# PIC32CM5112SG00100 device description
Architecture: CORTEX-M23; Family: PIC32CM; Series: PIC32CMSG00
Registers are 32-bit, read-write, reset 0x0 unless marked. A register's access mark holds for its fields unless they carry their own. Offsets are from the block's base; [hi:lo] are bit positions; lines under a group give offsets from that group; {n}, {i} and the like mark numbered series; 'fields as' and 'values as' point back to an identical list; <NAME> marks a mode.

## ICB — Implementation Control Block
Instances: ICB 0xE000E000, ICB_NS 0xE002E000
0x04 ICTR ro reset not defined — Interrupt Controller Type Register
  [3:0] INTLINESNUM — Interrupt line set number
0x08 ACTLR reset not defined — Auxiliary Control Register

## IDAU — Implementation Defined Attribution Unit
Instances: IDAU 0x44012000
0x00 CTRL wo — Control
  [31:16] CMD — Command Register
    0xA501=ENABLE (Module Enable); 0xA502=DISABLE (Module Disable); 0xA503=WLCK (Write Lock)
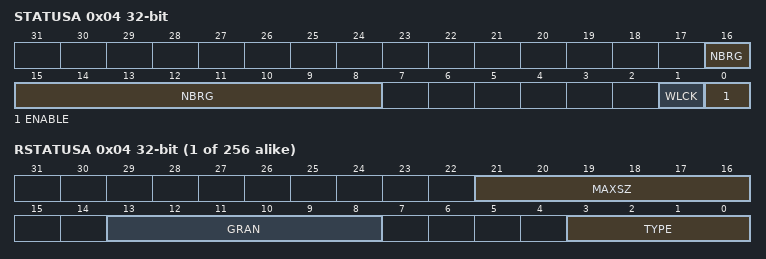
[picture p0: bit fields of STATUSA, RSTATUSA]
0x04 STATUSA ro reset not defined
  [16:8] NBRG — Number Of IDAU Regions
  [1] WLCK — Write Lock
  [0] ENABLE
0x08 STATUSB (atomic clear)
  [0] CFGERR — Configuration Error
{0x1000+0x10*i} REGIONS[{i}] (i=0..255) group
  0x00 RCTRL wo — Region Control
    [31:24] CMD <BLOCK> — Command
      90=CLRNONSEC (Clear IDAU region x Non-Secure State of block ARG (RSTATUSB[x].NONSEC[ARG]=0)); 91=SETNONSEC (Set IDAU region x Non-Secure State of block ARG (RSTATUSB[x].NONSEC[ARG]=1))
    [4:0] ARG <BLOCK> — Command Argument (Block ID)
    [31:24] CMD <WATERMARK> — Command
      92=WRSZ (Write IDAU region x Size (RSTATUSB[x].SIZE=ARG))
    [23:0] ARG <WATERMARK> — Command Argument (Watermark)
  0x04 RSTATUSA ro — Region Status A
    [21:16] MAXSZ — Command Argument Maximum Size
    [13:8] GRAN — Region Granularity
      0=GRAN_NA (Not Applicable); 5=GRAN_32B; 6=GRAN_64B; 7=GRAN_128B; 8=GRAN_256B; 9=GRAN_512B; 10=GRAN_1KB; 11=GRAN_2KB; 12=GRAN_4KB; 13=GRAN_8KB; 14=GRAN_16KB; 15=GRAN_32KB; 16=GRAN_64KB; 17=GRAN_128KB; 18=GRAN_256KB; 19=GRAN_512KB; 20=GRAN_1MB; 21=GRAN_2MB; 22=GRAN_4MB; 23=GRAN_8MB; 24=GRAN_16MB; 25=GRAN_32MB; 26=GRAN_64MB; 27=GRAN_128MB; 28=GRAN_256MB; 29=GRAN_512MB; 30=GRAN_1GB; 31=GRAN_2GB; 32=GRAN_4GB
    [3:0] TYPE — IDAU Region Type
      0=INVALID (Region is invalid); 1=SEC (Region is secure); 2=NONSEC (Region is non secure); 3=NONSEC_W (Region is non secure, the associated register group implements a watermark configuration); 4=SECnNONSEC_B (Region is either secure or non-secure, the associated register group implements a block configuration); 5=SECnNONSEC_L (Region is either secure or non-secure, configuration is linked to another IDAU region configuration bit (the linked configuration bit identification info is readable from the RSTATUSC register inside the same register group)); 6=NSC_W (Region is non-secure callable, the associated register group implements a watermark configuration); 7=EXEMPT_B (Region is exempt from security, the associated register group implements a block configuration)
  0x08 RSTATUSB ro — Region Status B
    [31:0] NONSEC <BLOCK> — Block Based Region Non-Secure State
    [31:0] SIZE <WATERMARK> — Watermark Based Region Size in Bytes
  0x0C RSTATUSC ro — Region Status C
    [31:0] CST <BLOCK> — Constant Block Configuration
    [12:8] BLK <LINK> — Linked IDAU Region Block ID
    [7:0] RGN <LINK> — Linked IDAU Region ID

## MCLK — Polaris Main Clock Controller
Instances: MCLK 0x4400A000
0x00 INTENCLR (atomic clear) — Interrupt Enable Clear Register
  [0] CKRDY — Clock Ready Interrupt Enable Clear
    0=The Clock Ready interrupt is disabled; 1=The Clock Ready interrupt is enabled
0x04 INTENSET (atomic set) — Interrupt Enable Set Register
  [0] CKRDY — Clock Ready Interrupt Enable Set
    values as INTENCLR.CKRDY
0x08 INTFLAG wo reset 0x1 (atomic clear) — Interrupt Flag Status Register
  [0] CKRDY — Clock Ready Interrupt Flag
{0xC+4i} CLKDIV[{i}] (i=0..2) — Clock Divider Control n Register
  [7:0] DIV — Clock Domain n Division Factor
    1=Divide by 1; 2=Divide by 2; 4=Divide by 4; 8=Divide by 8; 16=Divide by 16; 32=Divide by 32; 64=Divide by 64; 128=Divide by 128
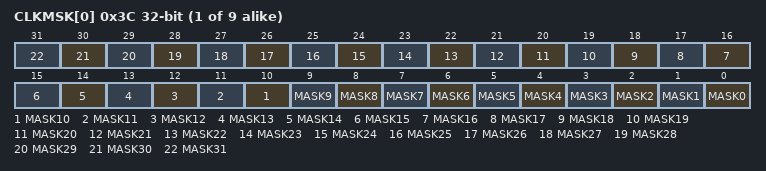
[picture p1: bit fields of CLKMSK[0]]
{0x3C+4i} CLKMSK[{i}] (i=0..8) — Peripheral Clock Enable Mask n Register
  [all] fields
    0=Peripheral clock mclk_clk_periph[n*32+x] stopped; 1=Peripheral clock mclk_clk_periph[n*32+x] enabled
  [n] MASK{n} (n=0..31) — Peripheral Clock Enable Mask
